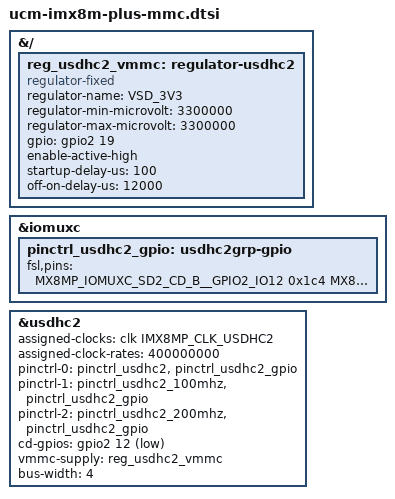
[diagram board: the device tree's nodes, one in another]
&{/} {
	reg_usdhc2_vmmc: regulator-usdhc2 {
		compatible = "regulator-fixed";
		regulator-name = "VSD_3V3";
		regulator-min-microvolt = <3300000>;
		regulator-max-microvolt = <3300000>;
		gpio = <&gpio2 19 GPIO_ACTIVE_HIGH>;
		enable-active-high;
		startup-delay-us = <100>;
		off-on-delay-us = <12000>;
	};
};

&iomuxc {
	pinctrl_usdhc2_gpio: usdhc2grp-gpio {
		fsl,pins = <
			MX8MP_IOMUXC_SD2_CD_B__GPIO2_IO12 	0x1c4
			MX8MP_IOMUXC_SD2_RESET_B__GPIO2_IO19	0x41
		>;
	};
};

&usdhc2 {
	assigned-clocks = <&clk IMX8MP_CLK_USDHC2>;
	assigned-clock-rates = <400000000>;
	pinctrl-names = "default", "state_100mhz", "state_200mhz";
	pinctrl-0 = <&pinctrl_usdhc2>, <&pinctrl_usdhc2_gpio>;
	pinctrl-1 = <&pinctrl_usdhc2_100mhz>, <&pinctrl_usdhc2_gpio>;
	pinctrl-2 = <&pinctrl_usdhc2_200mhz>, <&pinctrl_usdhc2_gpio>;
	cd-gpios = <&gpio2 12 GPIO_ACTIVE_LOW>;
	vmmc-supply = <&reg_usdhc2_vmmc>;
	bus-width = <4>;
	status = "okay";
};
